# STM32F0x0 register map
File version: 1.2
CPU: CM0 r0p0, little endian, no MPU, no FPU, 3 interrupt priority bits
Registers are 32-bit, read-write, reset 0x0 unless marked. A register's access mark holds for its fields unless they carry their own. Offsets are from the block's base; [hi:lo] are bit positions; {n}, {i} and the like mark numbered series.

## CRC — cyclic redundancy check calculation unit
Base 0x40023000
0x00 DR reset 0xFFFFFFFF — Data register
  [31:0] DR — Data register bits
0x04 IDR — Independent data register
  [7:0] IDR — General-purpose 8-bit data register bits
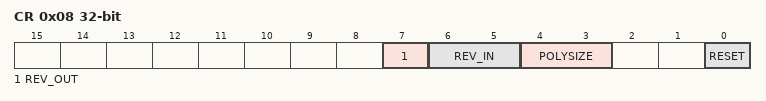
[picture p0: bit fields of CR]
0x08 CR — Control register
  [7] REV_OUT — Reverse output data
  [6:5] REV_IN — Reverse input data
  [4:3] POLYSIZE — Polynomial size
  [0] RESET — reset bit
0x0C INIT reset 0xFFFFFFFF — Initial CRC value
  [31:0] INIT — Programmable initial CRC value

## PWR — Power control
Base 0x40007000
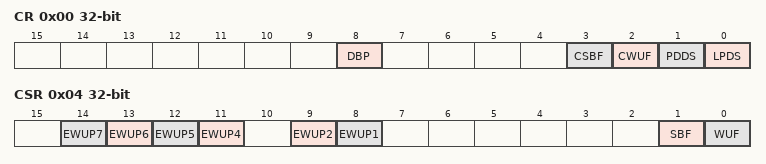
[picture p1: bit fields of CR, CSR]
0x00 CR — power control register
  [8] DBP — Disable backup domain write protection
  [3] CSBF — Clear standby flag
  [2] CWUF — Clear wakeup flag
  [1] PDDS — Power down deepsleep
  [0] LPDS — Low-power deep sleep
0x04 CSR access per field — power control/status register
  [n+7] EWUP{n} rw (n=4..7) — Enable WKUP pin {n}
  [9] EWUP2 rw — Enable WKUP pin 2
  [8] EWUP1 rw — Enable WKUP pin 1
  [1] SBF ro — Standby flag
  [0] WUF ro — Wakeup flag

## IWDG — Independent watchdog
Base 0x40003000
0x00 KR wo — Key register
  [15:0] KEY — Key value
0x04 PR — Prescaler register
  [2:0] PR — Prescaler divider
0x08 RLR reset 0xFFF — Reload register
  [11:0] RL — Watchdog counter reload value
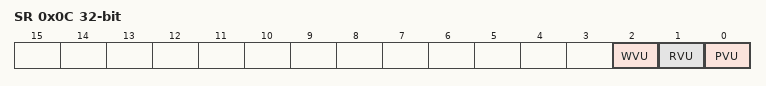
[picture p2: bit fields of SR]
0x0C SR ro — Status register
  [2] WVU — Watchdog counter window value update
  [1] RVU — Watchdog counter reload value update
  [0] PVU — Watchdog prescaler value update
0x10 WINR reset 0xFFF — Window register
  [11:0] WIN — Watchdog counter window value

## WWDG — Window watchdog
Base 0x40002C00
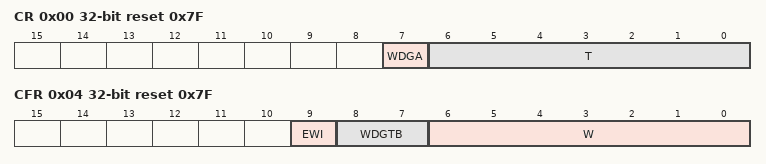
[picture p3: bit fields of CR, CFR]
0x00 CR reset 0x7F — Control register
  [7] WDGA — Activation bit
  [6:0] T — 7-bit counter
0x04 CFR reset 0x7F — Configuration register
  [9] EWI — Early wakeup interrupt
  [8:7] WDGTB — Timer base
  [6:0] W — 7-bit window value
0x08 SR — Status register
  [0] EWIF — Early wakeup interrupt flag

## EXTI — External interrupt/event controller
Base 0x40010400
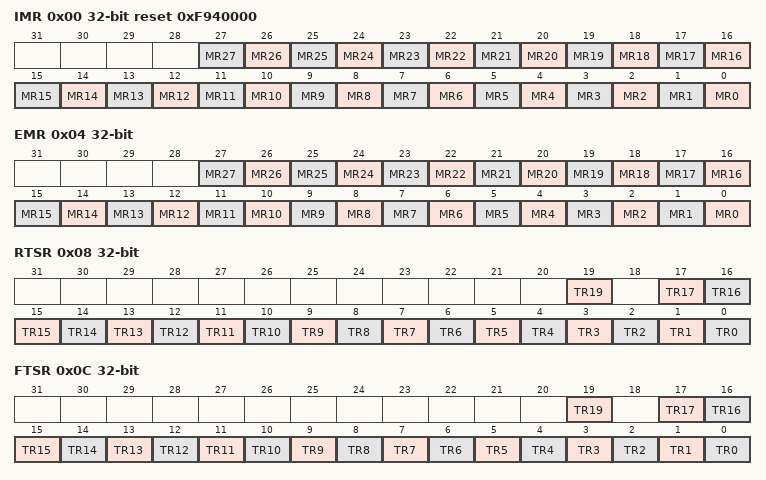
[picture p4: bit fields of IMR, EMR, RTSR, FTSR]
0x00 IMR reset 0xF940000 — Interrupt mask register (EXTI_IMR)
  [n] MR{n} (n=0..27) — Interrupt Mask on line {n}
0x04 EMR — Event mask register (EXTI_EMR)
  [n] MR{n} (n=0..27) — Event Mask on line {n}
0x08 RTSR — Rising Trigger selection register (EXTI_RTSR)
  [19] TR19 — Rising trigger event configuration of line 19
  [n] TR{n} (n=0..17) — Rising trigger event configuration of line {n}
0x0C FTSR — Falling Trigger selection register (EXTI_FTSR)
  [19] TR19 — Falling trigger event configuration of line 19
  [n] TR{n} (n=0..17) — Falling trigger event configuration of line {n}
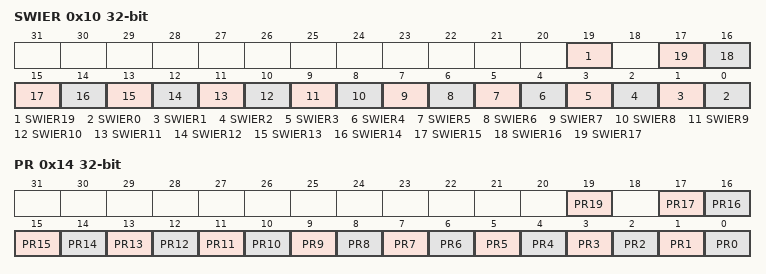
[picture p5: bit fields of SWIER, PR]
0x10 SWIER — Software interrupt event register (EXTI_SWIER)
  [19] SWIER19 — Software Interrupt on line 19
  [n] SWIER{n} (n=0..17) — Software Interrupt on line {n}
0x14 PR — Pending register (EXTI_PR)
  [19] PR19 — Pending bit 19
  [n] PR{n} (n=0..17) — Pending bit {n}

## NVIC — Nested Vectored Interrupt Controller
Base 0xE000E100
0x00 ISER — Interrupt Set Enable Register
  [31:0] SETENA
0x80 ICER — Interrupt Clear Enable Register
  [31:0] CLRENA
0x100 ISPR — Interrupt Set-Pending Register
  [31:0] SETPEND
0x180 ICPR — Interrupt Clear-Pending Register
  [31:0] CLRPEND
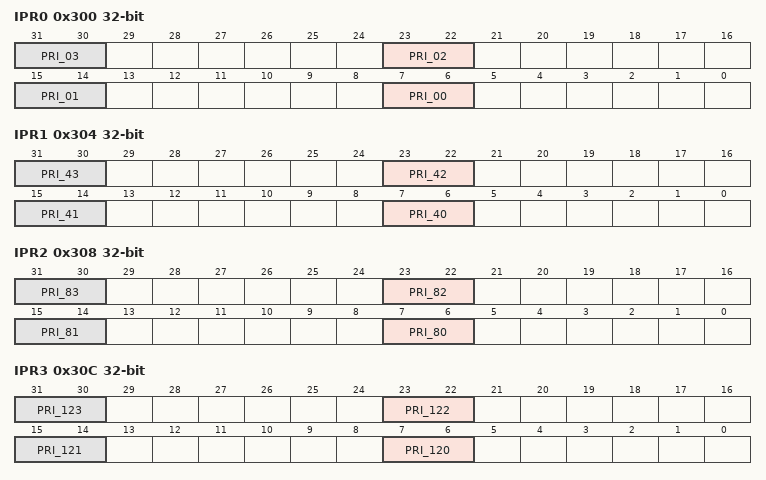
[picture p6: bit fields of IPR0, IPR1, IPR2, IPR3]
0x300 IPR0 — Interrupt Priority Register 0
  [8n+7:8n+6] PRI_{n:02} (n=0..3)
0x304 IPR1 — Interrupt Priority Register 1
  [8n-313:8n-314] PRI_{n} (n=40..43)
0x308 IPR2 — Interrupt Priority Register 2
  [8n-633:8n-634] PRI_{n} (n=80..83)
0x30C IPR3 — Interrupt Priority Register 3
  [8n-953:8n-954] PRI_{n} (n=120..123)
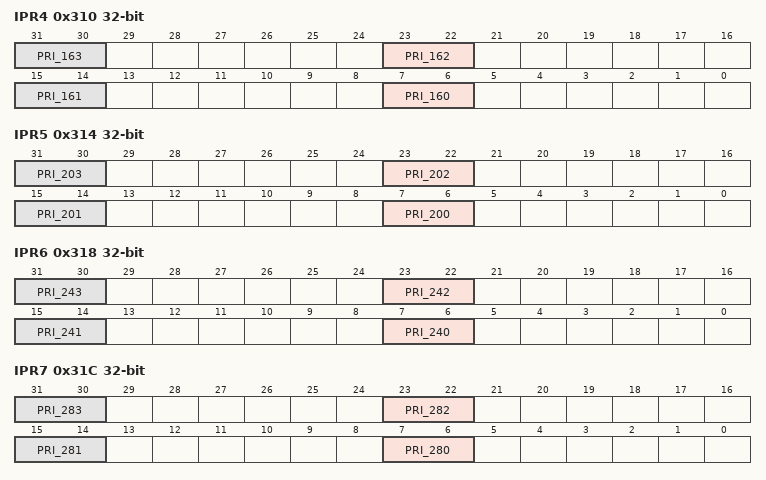
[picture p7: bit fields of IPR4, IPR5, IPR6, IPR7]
0x310 IPR4 — Interrupt Priority Register 4
  [8n-1273:8n-1274] PRI_{n} (n=160..163)
0x314 IPR5 — Interrupt Priority Register 5
  [8n-1593:8n-1594] PRI_{n} (n=200..203)
0x318 IPR6 — Interrupt Priority Register 6
  [8n-1913:8n-1914] PRI_{n} (n=240..243)
0x31C IPR7 — Interrupt Priority Register 7
  [8n-2233:8n-2234] PRI_{n} (n=280..283)
